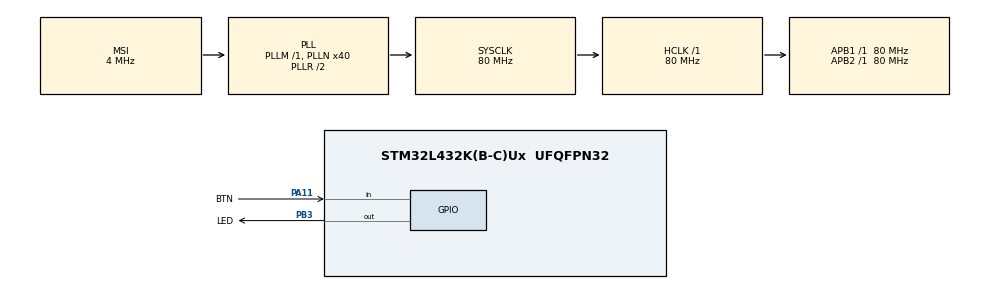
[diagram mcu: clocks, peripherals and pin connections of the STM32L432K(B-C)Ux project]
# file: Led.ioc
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Mcu.Family=STM32L4
Mcu.Name=STM32L432K(B-C)Ux
Mcu.Package=UFQFPN32
NVIC.PriorityGroup=NVIC_PRIORITYGROUP_4
PA11.GPIO_Label=BTN
PA11.Signal=GPIO_Input
PB3\ (JTDO-TRACESWO).GPIO_Label=LED
PB3\ (JTDO-TRACESWO).GPIO_PuPd=GPIO_PULLDOWN
PB3\ (JTDO-TRACESWO).Signal=GPIO_Output
ProjectManager.HeapSize=0x0
ProjectManager.StackSize=0x400
ProjectManager.TargetToolchain=Other Toolchains (GPDSC)
RCC.AHBFreq_Value=80000000
RCC.APB1Freq_Value=80000000
RCC.APB1TimFreq_Value=80000000
RCC.APB2Freq_Value=80000000
RCC.APB2TimFreq_Value=80000000
RCC.CortexFreq_Value=80000000
RCC.HCLKFreq_Value=80000000
RCC.HSE_VALUE=8000000
RCC.HSI48_VALUE=48000000
RCC.HSI_VALUE=16000000
RCC.LSE_VALUE=32768
RCC.MSI_VALUE=4000000
RCC.PLLN=40
RCC.SYSCLKFreq_VALUE=80000000
RCC.SYSCLKSource=RCC_SYSCLKSOURCE_PLLCLK
RCC.VCOOutputFreq_Value=160000000
board=custom

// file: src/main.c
/* USER CODE BEGIN Header */
/**
 ******************************************************************************
 * @file           : main.c
 * @brief          : Main program body
 ******************************************************************************
 * @attention
 *
 * <h2><center>&copy; Copyright (c) 2021 STMicroelectronics.
 * All rights reserved.</center></h2>
 *
 * This software component is licensed by ST under BSD 3-Clause license,
 * the "License"; You may not use this file except in compliance with the
 * License. You may obtain a copy of the License at:
 *                        opensource.org/licenses/BSD-3-Clause
 *
 ******************************************************************************
 */
/* USER CODE END Header */
#include "main.h"
#include "gpio.h"

/* USER CODE BEGIN Includes */
#include "luos_engine.h"
#include "robus_network.h"
#include "led.h"
/* USER CODE END Includes */

void SystemClock_Config(void);

int main(void)
{

    /* MCU Configuration--------------------------------------------------------*/

    /* Reset of all peripherals, Initializes the Flash interface and the Systick. */
    HAL_Init();

    /* Configure the system clock */
    SystemClock_Config();

    /* Initialize all configured peripherals */
    MX_GPIO_Init();
    /* USER CODE BEGIN 2 */
    Luos_Init();
    Robus_Init();
    Led_Init();
    /* USER CODE END 2 */

    /* Infinite loop */
    while (1)
    {

        /* USER CODE BEGIN 3 */
        Luos_Loop();
        Led_Loop();
    }
    /* USER CODE END 3 */
}

void SystemClock_Config(void)
{
    RCC_OscInitTypeDef RCC_OscInitStruct = {0};
    RCC_ClkInitTypeDef RCC_ClkInitStruct = {0};

    /** Initializes the RCC Oscillators according to the specified parameters
     * in the RCC_OscInitTypeDef structure.
     */
    RCC_OscInitStruct.OscillatorType      = RCC_OSCILLATORTYPE_MSI;
    RCC_OscInitStruct.MSIState            = RCC_MSI_ON;
    RCC_OscInitStruct.MSICalibrationValue = 0;
    RCC_OscInitStruct.MSIClockRange       = RCC_MSIRANGE_6;
    RCC_OscInitStruct.PLL.PLLState        = RCC_PLL_ON;
    RCC_OscInitStruct.PLL.PLLSource       = RCC_PLLSOURCE_MSI;
    RCC_OscInitStruct.PLL.PLLM            = 1;
    RCC_OscInitStruct.PLL.PLLN            = 40;
    RCC_OscInitStruct.PLL.PLLP            = RCC_PLLP_DIV7;
    RCC_OscInitStruct.PLL.PLLQ            = RCC_PLLQ_DIV2;
    RCC_OscInitStruct.PLL.PLLR            = RCC_PLLR_DIV2;
    if (HAL_RCC_OscConfig(&RCC_OscInitStruct) != HAL_OK)
    {
        Error_Handler();
    }
    /** Initializes the CPU, AHB and APB buses clocks
     */
    RCC_ClkInitStruct.ClockType = RCC_CLOCKTYPE_HCLK | RCC_CLOCKTYPE_SYSCLK
                                  | RCC_CLOCKTYPE_PCLK1 | RCC_CLOCKTYPE_PCLK2;
    RCC_ClkInitStruct.SYSCLKSource   = RCC_SYSCLKSOURCE_PLLCLK;
    RCC_ClkInitStruct.AHBCLKDivider  = RCC_SYSCLK_DIV1;
    RCC_ClkInitStruct.APB1CLKDivider = RCC_HCLK_DIV1;
    RCC_ClkInitStruct.APB2CLKDivider = RCC_HCLK_DIV1;

    if (HAL_RCC_ClockConfig(&RCC_ClkInitStruct, FLASH_LATENCY_4) != HAL_OK)
    {
        Error_Handler();
    }
    /** Configure the main internal regulator output voltage
     */
    if (HAL_PWREx_ControlVoltageScaling(PWR_REGULATOR_VOLTAGE_SCALE1) != HAL_OK)
    {
        Error_Handler();
    }
}

void Error_Handler(void)
{
    __disable_irq();
    while (1)
    {
    }
}

/************************ (C) COPYRIGHT STMicroelectronics *****END OF FILE****/
